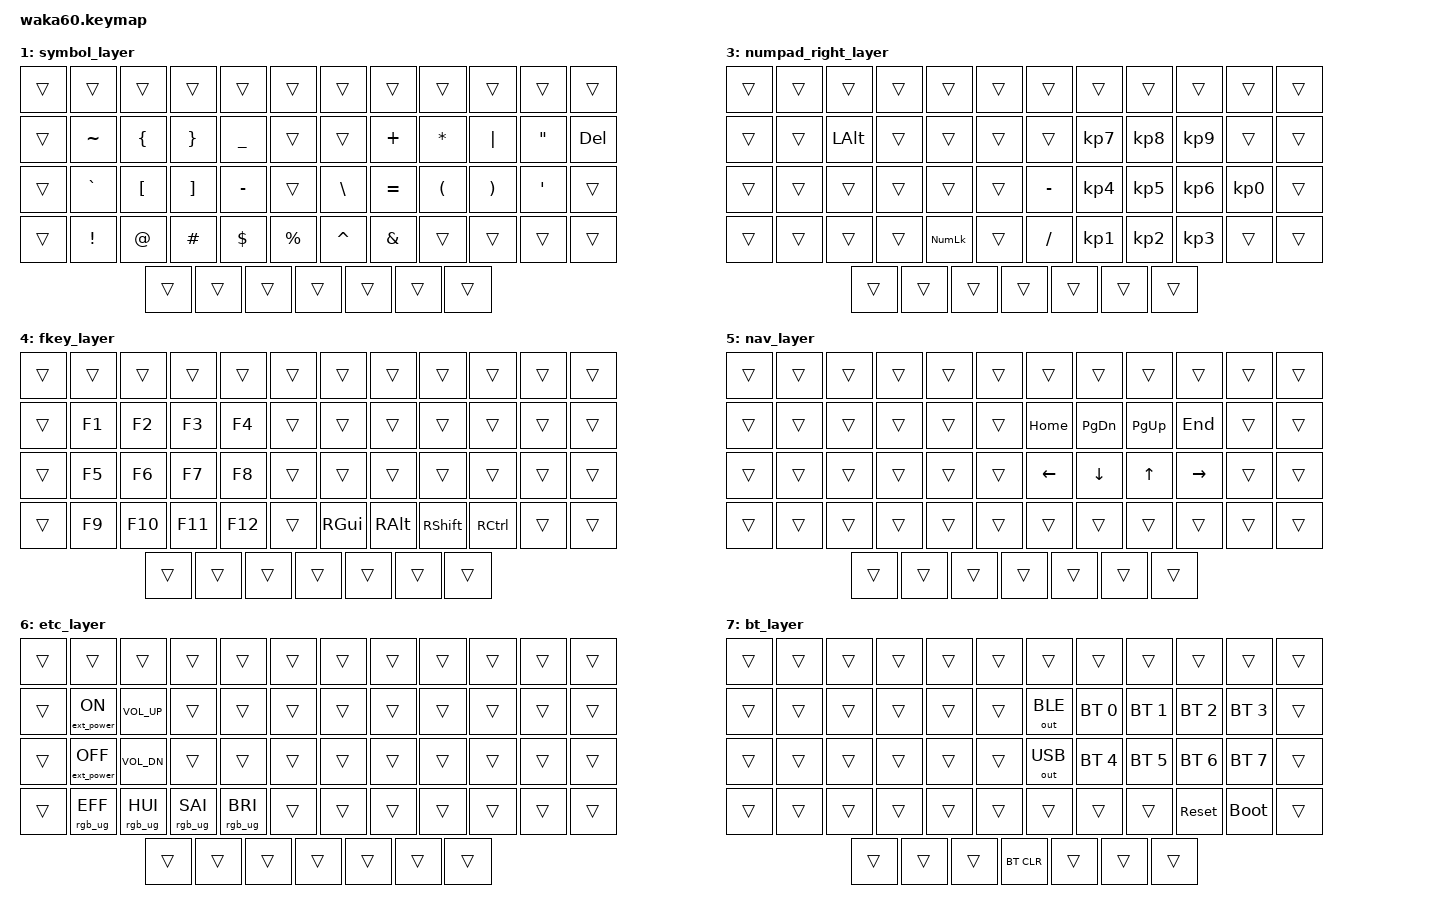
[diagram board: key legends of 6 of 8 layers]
/*
 * Copyright (c) 2023 The ZMK Contributors
 *
 * SPDX-License-Identifier: MIT
 */

#include <behaviors.dtsi>
#include <dt-bindings/zmk/bt.h>
#include <dt-bindings/zmk/ext_power.h>
#include <dt-bindings/zmk/keys.h>
#include <dt-bindings/zmk/outputs.h>
#include <dt-bindings/zmk/rgb.h>

#include "less_behaviors.dtsi"
/*
  TODO: rewrite all my combos because of position-based numbering, thanks ZMK!
  #include "s40nc_combos.dtsi"
*/
#include "less_macros.dtsi"

&qdec_encoder {
    status = "okay";
};

&sensors {
    sensors = <&qdec_encoder>;
};

/ {

    chosen { zmk,matrix-transform = &full_space_transform; };

    behaviors {
        rgb_rotation: encoder_rotation {
            compatible = "zmk,behavior-sensor-rotate";
            #sensor-binding-cells = <0>;
            bindings = <&rgb_ug RGB_BRI>, <&rgb_ug RGB_BRD>;
        };
    };

    keymap {
        compatible = "zmk,keymap";

        default_layer {
            bindings = <
                &trans  &trans  &trans  &trans  &trans  &trans     &trans  &trans  &trans  &trans  &trans  &trans
                &kp ESC        &lt 3 Q     &kp W        &kp E        &kp R        &kp T        &kp Y        &kp U       &kp I           &kp O        &lt 6 P     &kp BSPC
                &mt LCTRL TAB  &mt LALT A  &mt LCTRL S  &mt LSHFT D  &mt LGUI F   &kp G        &kp H        &mt RGUI J  &mt RSHFT K     &mt RCTRL L  &mt RALT SEMI
                &kp LSHFT      &lt 7 Z     &kp X        &kp C        &kp V        &kp B        &kp N        &kp M       &kp COMMA       &kp DOT      &lt 4 FSLH
                &kp C_MENU     &kp LGUI    &mo_tog 5 5               &lt 1 SPACE               &mo_tog 2 2  &kp RGUI    &mt RCTRL CAPS  &kp C_MUTE
            >;
            sensor-bindings = <&inc_dec_kp C_VOL_UP C_VOL_DN>;
        };
        symbol_layer {
            bindings = <
                &trans  &trans  &trans  &trans  &trans  &trans     &trans  &trans  &trans  &trans  &trans  &trans
                &trans  &kp TILDE  &kp LBRC  &kp RBRC  &kp UNDER &trans     &trans     &kp PLUS  &kp STAR  &kp PIPE  &kp DQT  &kp DEL
                &trans  &kp GRAVE  &kp LBKT  &kp RBKT  &kp MINUS &trans     &kp BSLH   &kp EQUAL &kp LPAR  &kp RPAR  &kp SQT  &trans
                &trans  &kp EXCL   &kp AT    &kp HASH  &kp DLLR  &kp PRCNT  &kp CARET  &kp AMPS  &trans    &trans    &trans   &trans
                &trans  &trans     &trans                              &trans                              &trans    &trans   &trans
            >;
        };

        numpad_left_layer {
            bindings = <
                &trans  &trans  &trans  &trans  &trans  &trans     &trans  &trans  &trans  &trans  &trans  &trans
                &trans  &trans  &kp N7  &kp N8  &kp N9  &trans     &trans  &trans  &trans  &trans  &trans  &trans
                &trans  &kp N0  &kp N4  &kp N5  &kp N6  &kp MINUS  &trans  &trans  &trans  &trans  &trans
                &trans  &trans  &kp N1  &kp N2  &kp N3  &kp FSLH   &trans  &trans  &trans  &trans  &trans
                &trans  &trans  &trans                  &trans                     &trans  &trans  &trans    &trans
            >;
        };

        numpad_right_layer {
            bindings = <
                &trans  &trans  &trans  &trans  &trans  &trans     &trans  &trans  &trans  &trans  &trans  &trans
                &trans  &trans  &kp LALT  &trans  &trans      &trans  &trans     &kp KP_N7  &kp KP_N8  &kp KP_N9  &trans     &trans
                &trans  &trans  &trans    &trans  &trans      &trans  &kp MINUS  &kp KP_N4  &kp KP_N5  &kp KP_N6  &kp KP_N0  &trans
                &trans  &trans  &trans    &trans  &kp KP_NUM  &trans  &kp FSLH   &kp KP_N1  &kp KP_N2  &kp KP_N3  &trans     &trans
                &trans  &trans  &trans                        &trans                        &trans     &trans     &trans
            >;
        };

        fkey_layer {
            bindings = <
                &trans  &trans  &trans  &trans  &trans  &trans     &trans  &trans  &trans  &trans  &trans  &trans
                &trans  &kp F1  &kp F2  &kp F3  &kp F4    &trans  &trans    &trans     &trans     &trans     &trans    &trans
                &trans  &kp F5  &kp F6  &kp F7  &kp F8    &trans  &trans    &trans     &trans     &trans     &trans    &trans
                &trans  &kp F9  &kp F10 &kp F11 &kp F12   &trans  &kp RGUI  &kp RALT   &kp RSHFT  &kp RCTRL  &trans    &trans
                &trans  &trans  &trans                    &trans                       &trans     &trans     &trans
            >;
        };

        nav_layer {
            bindings = <
                &trans  &trans  &trans  &trans  &trans  &trans     &trans  &trans  &trans  &trans  &trans  &trans
                &trans  &trans    &trans  &trans  &trans  &trans  &kp HOME  &kp PG_DN  &kp PG_UP  &kp END    &trans    &trans
                &trans  &trans    &trans  &trans  &trans  &trans  &kp LEFT  &kp DOWN   &kp UP     &kp RIGHT  &trans    &trans
                &trans  &trans    &trans  &trans  &trans  &trans  &trans    &trans     &trans     &trans     &trans    &trans
                &trans  &trans    &trans                  &trans                       &trans     &trans     &trans
            >;
        };

        etc_layer {
            bindings = <
                &trans  &trans  &trans  &trans  &trans  &trans     &trans  &trans  &trans  &trans  &trans  &trans
                &trans  &ext_power EP_ON   &kp C_VOL_UP     &trans  &trans  &trans  &trans  &trans  &trans  &trans  &trans  &trans
                &trans  &ext_power EP_OFF  &kp C_VOL_DN     &trans  &trans  &trans  &trans  &trans  &trans  &trans  &trans  &trans
                &trans  &rgb_ug RGB_EFF    &rgb_ug RGB_HUI  &rgb_ug RGB_SAI  &rgb_ug RGB_BRI  &trans  &trans  &trans  &trans  &trans  &trans  &trans
                &trans  &trans             &trans                        &trans                  &trans  &trans  &trans
            >;
            sensor-bindings = <&rgb_rotation>;
        };

        bt_layer {
            bindings = <
                &trans  &trans  &trans  &trans  &trans  &trans     &trans  &trans  &trans  &trans  &trans  &trans
                &trans  &trans  &trans  &trans      &trans  &trans      &out OUT_BLE  &bt BT_SEL 0  &bt BT_SEL 1  &bt BT_SEL 2  &bt BT_SEL 3  &trans
                &trans  &trans  &trans  &trans      &trans  &trans      &out OUT_USB  &bt BT_SEL 4  &bt BT_SEL 5  &bt BT_SEL 6  &bt BT_SEL 7  &trans
                &trans  &trans  &trans  &trans      &trans  &trans      &trans        &trans        &trans        &sys_reset    &bootloader   &trans
                &trans  &trans  &trans                      &bt BT_CLR                              &trans        &trans        &trans
            >;
        };
    };
};
